# M4G7 register map
File version: 0.1
Registers are 32-bit, read-write, reset 0x0 unless marked. A register's access mark holds for its fields unless they carry their own. Offsets are from the block's base; [hi:lo] are bit positions; {n}, {i} and the like mark numbered series; 'fields as' and 'values as' point back to an identical list.

## SMI
Base 0x4000C000
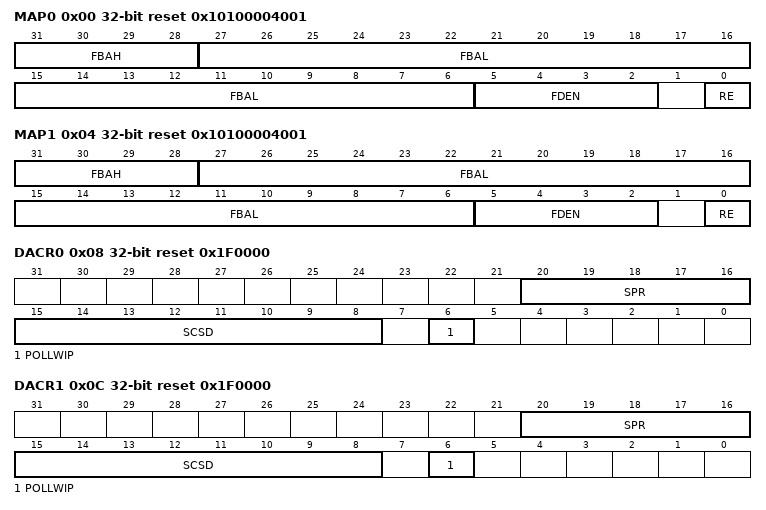
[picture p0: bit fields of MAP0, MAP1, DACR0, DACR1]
0x00 MAP0 reset 0x10100004001 — SMIF Flash Memory Map0 Register
  [31:28] FBAH ro, [27:6] FBAL, [5:2] FDEN, [0] RE
0x04 MAP1 reset 0x10100004001 — SMIF Flash Memory Map1 Register
  [31:28] FBAH ro, [27:6] FBAL, [5:2] FDEN, [0] RE
0x08 DACR0 reset 0x1F0000 — SMIF Direct Access Control Register 0
  [20:16] SPR, [15:8] SCSD, [6] POLLWIP
0x0C DACR1 reset 0x1F0000 — SMIF Direct Access Control Register 1
  [20:16] SPR, [15:8] SCSD, [6] POLLWIP
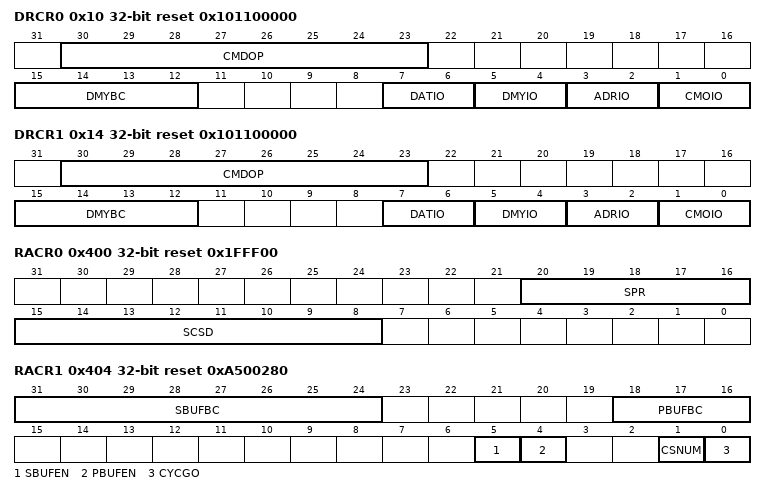
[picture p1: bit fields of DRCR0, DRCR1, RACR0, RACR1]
0x10 DRCR0 reset 0x101100000 — SMIF Direct Read Control Register 0
  [30:23] CMDOP, [15:12] DMYBC, [7:6] DATIO, [5:4] DMYIO, [3:2] ADRIO, [1:0] CMOIO
0x14 DRCR1 reset 0x101100000 — SMIF Direct Read Control Register 1
  fields as DRCR0
0x400 RACR0 reset 0x1FFF00 — SMIF Program Register Access Control Register 0
  [20:16] SPR, [15:8] SCSD
0x404 RACR1 reset 0xA500280 — SMIF Program Register Access Control Register 1
  [31:24] SBUFBC, [18:16] PBUFBC, [5] SBUFEN, [4] PBUFEN, [1] CSNUM, [0] CYCGO
0x408 INT — SMIF Program Register Access Interrupt Enable Register
  [0] INTEN
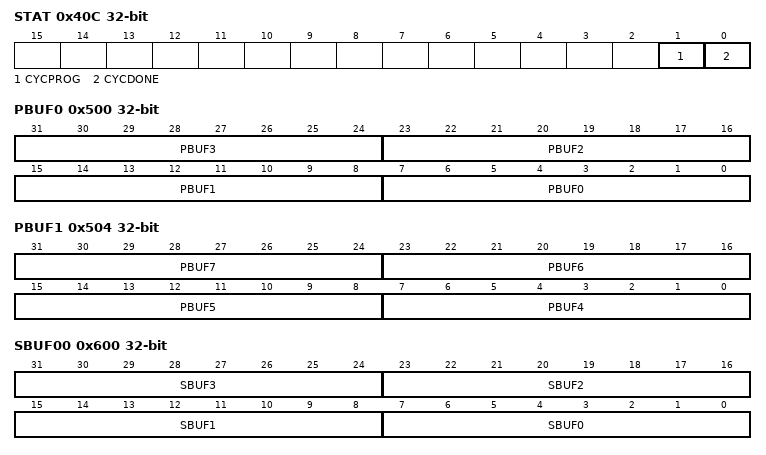
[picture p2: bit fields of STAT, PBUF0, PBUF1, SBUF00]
0x40C STAT — SMIF Program Register Access Status Register
  [1] CYCPROG ro, [0] CYCDONE
0x500 PBUF0 reset not defined — SMIF Program Register Primary Buffer Data Register 0
  [8n+7:8n] PBUF{n} (n=0..3)
0x504 PBUF1 reset not defined — SMIF Program Register Primary Buffer Data Register 1
  [8n-25:8n-32] PBUF{n} (n=4..7)
0x600 SBUF00 reset not defined — SMIF Program Register Secondary Buffer Data Register 00
  [8n+7:8n] SBUF{n} (n=0..3)
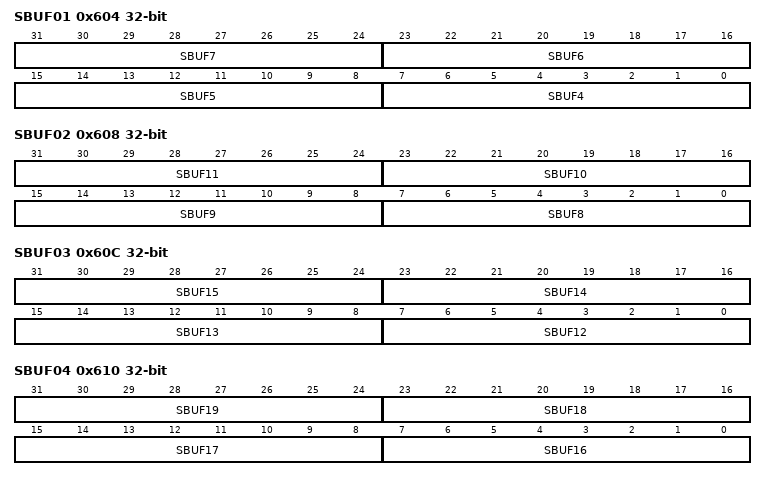
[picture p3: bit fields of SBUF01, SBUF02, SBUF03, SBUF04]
0x604 SBUF01 reset not defined — SMIF Program Register Secondary Buffer Data Register 01
  [8n-25:8n-32] SBUF{n} (n=4..7)
0x608 SBUF02 reset not defined — SMIF Program Register Secondary Buffer Data Register 02
  [8n-57:8n-64] SBUF{n} (n=8..11)
0x60C SBUF03 reset not defined — SMIF Program Register Secondary Buffer Data Register 03
  [8n-89:8n-96] SBUF{n} (n=12..15)
0x610 SBUF04 reset not defined — SMIF Program Register Secondary Buffer Data Register 04
  [8n-121:8n-128] SBUF{n} (n=16..19)
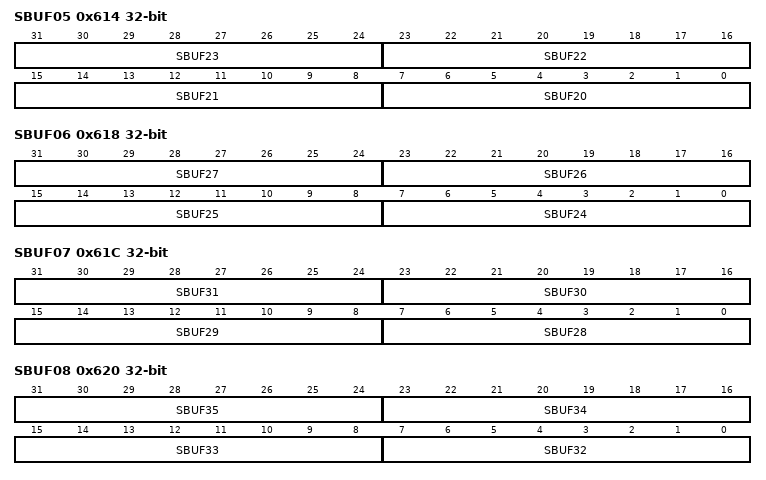
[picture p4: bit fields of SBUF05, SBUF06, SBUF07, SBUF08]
0x614 SBUF05 reset not defined — SMIF Program Register Secondary Buffer Data Register 05
  [8n-153:8n-160] SBUF{n} (n=20..23)
0x618 SBUF06 reset not defined — SMIF Program Register Secondary Buffer Data Register 06
  [8n-185:8n-192] SBUF{n} (n=24..27)
0x61C SBUF07 reset not defined — SMIF Program Register Secondary Buffer Data Register 07
  [8n-217:8n-224] SBUF{n} (n=28..31)
0x620 SBUF08 reset not defined — SMIF Program Register Secondary Buffer Data Register 08
  [8n-249:8n-256] SBUF{n} (n=32..35)
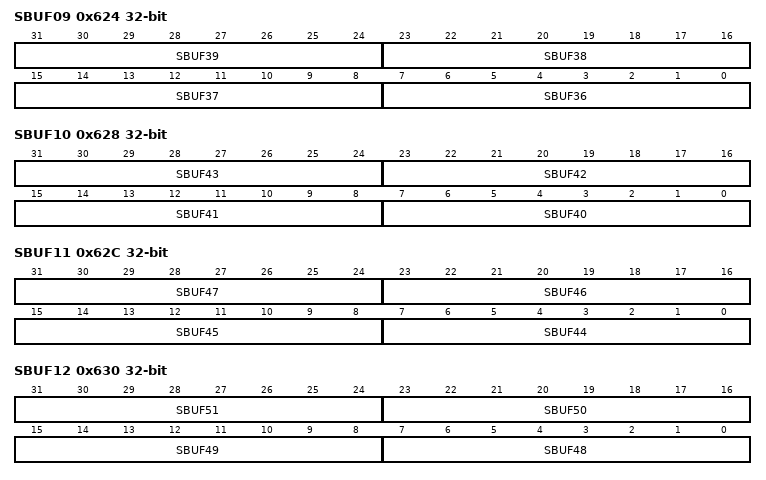
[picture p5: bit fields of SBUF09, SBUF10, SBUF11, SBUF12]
0x624 SBUF09 reset not defined — SMIF Program Register Secondary Buffer Data Register 09
  [8n-281:8n-288] SBUF{n} (n=36..39)
0x628 SBUF10 reset not defined — SMIF Program Register Secondary Buffer Data Register 10
  [8n-313:8n-320] SBUF{n} (n=40..43)
0x62C SBUF11 reset not defined — SMIF Program Register Secondary Buffer Data Register 11
  [8n-345:8n-352] SBUF{n} (n=44..47)
0x630 SBUF12 reset not defined — SMIF Program Register Secondary Buffer Data Register 12
  [8n-377:8n-384] SBUF{n} (n=48..51)
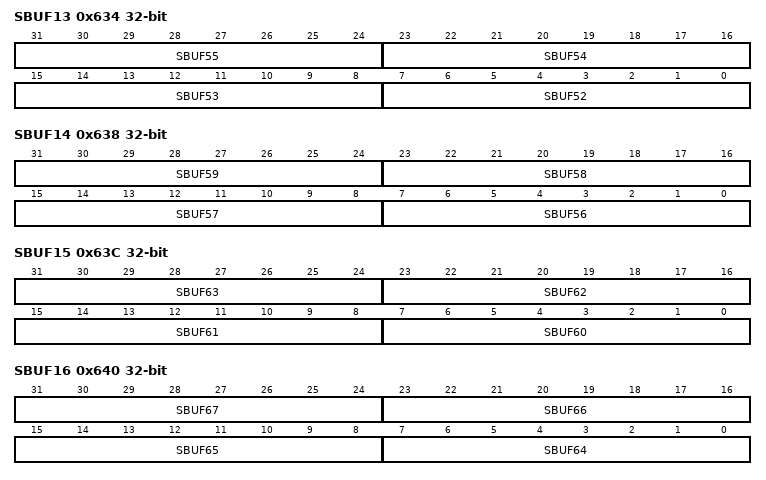
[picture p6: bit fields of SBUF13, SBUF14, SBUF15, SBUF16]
0x634 SBUF13 reset not defined — SMIF Program Register Secondary Buffer Data Register 13
  [8n-409:8n-416] SBUF{n} (n=52..55)
0x638 SBUF14 reset not defined — SMIF Program Register Secondary Buffer Data Register 14
  [8n-441:8n-448] SBUF{n} (n=56..59)
0x63C SBUF15 reset not defined — SMIF Program Register Secondary Buffer Data Register 15
  [8n-473:8n-480] SBUF{n} (n=60..63)
0x640 SBUF16 reset not defined — SMIF Program Register Secondary Buffer Data Register 16
  [8n-505:8n-512] SBUF{n} (n=64..67)
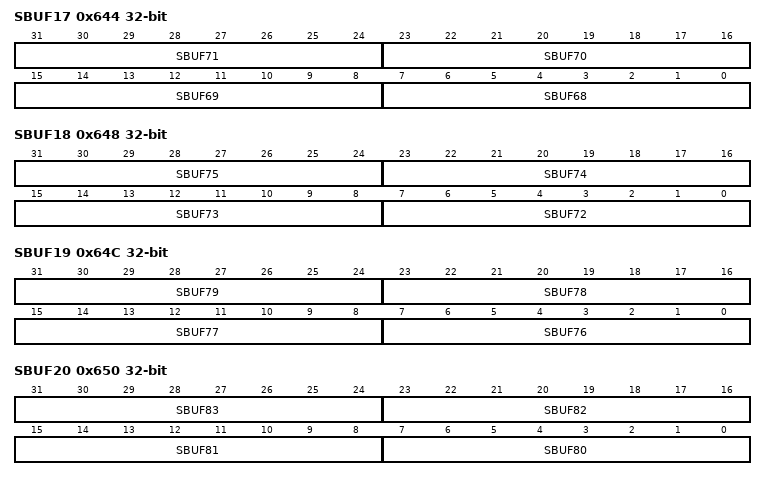
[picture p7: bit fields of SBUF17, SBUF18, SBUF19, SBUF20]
0x644 SBUF17 reset not defined — SMIF Program Register Secondary Buffer Data Register 17
  [8n-537:8n-544] SBUF{n} (n=68..71)
0x648 SBUF18 reset not defined — SMIF Program Register Secondary Buffer Data Register 18
  [8n-569:8n-576] SBUF{n} (n=72..75)
0x64C SBUF19 reset not defined — SMIF Program Register Secondary Buffer Data Register 19
  [8n-601:8n-608] SBUF{n} (n=76..79)
0x650 SBUF20 reset not defined — SMIF Program Register Secondary Buffer Data Register 20
  [8n-633:8n-640] SBUF{n} (n=80..83)
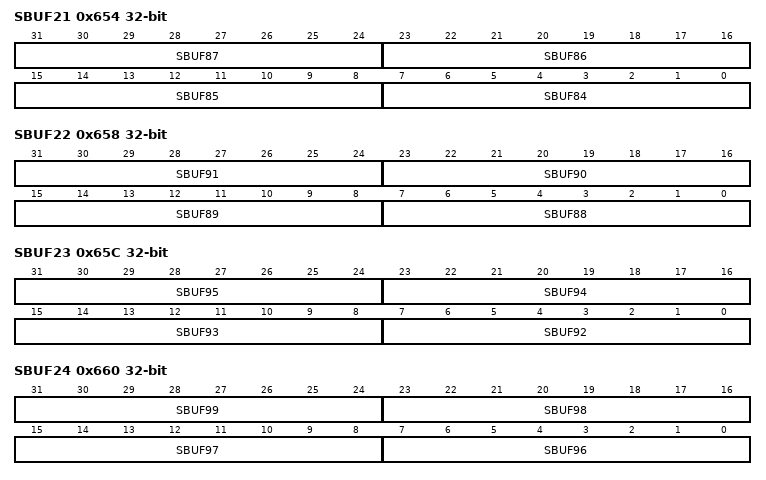
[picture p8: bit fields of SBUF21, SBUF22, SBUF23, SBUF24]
0x654 SBUF21 reset not defined — SMIF Program Register Secondary Buffer Data Register 21
  [8n-665:8n-672] SBUF{n} (n=84..87)
0x658 SBUF22 reset not defined — SMIF Program Register Secondary Buffer Data Register 22
  [8n-697:8n-704] SBUF{n} (n=88..91)
0x65C SBUF23 reset not defined — SMIF Program Register Secondary Buffer Data Register 23
  [8n-729:8n-736] SBUF{n} (n=92..95)
0x660 SBUF24 reset not defined — SMIF Program Register Secondary Buffer Data Register 24
  [8n-761:8n-768] SBUF{n} (n=96..99)
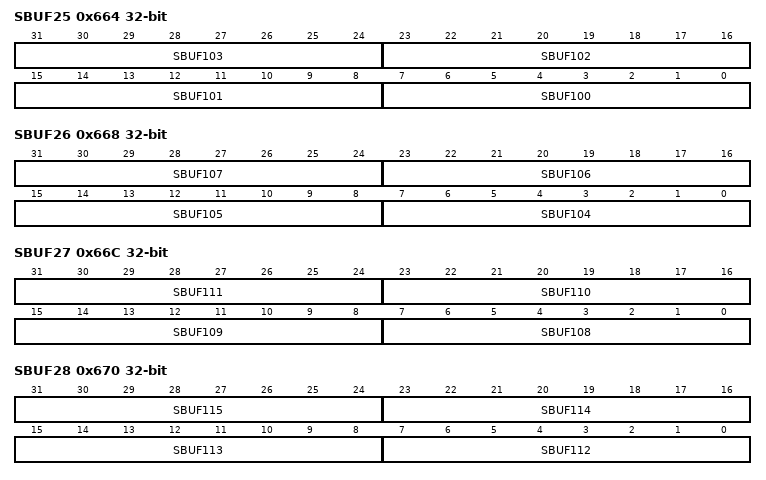
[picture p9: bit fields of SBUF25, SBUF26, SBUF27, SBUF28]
0x664 SBUF25 reset not defined — SMIF Program Register Secondary Buffer Data Register 25
  [8n-793:8n-800] SBUF{n} (n=100..103)
0x668 SBUF26 reset not defined — SMIF Program Register Secondary Buffer Data Register 26
  [8n-825:8n-832] SBUF{n} (n=104..107)
0x66C SBUF27 reset not defined — SMIF Program Register Secondary Buffer Data Register 27
  [8n-857:8n-864] SBUF{n} (n=108..111)
0x670 SBUF28 reset not defined — SMIF Program Register Secondary Buffer Data Register 28
  [8n-889:8n-896] SBUF{n} (n=112..115)
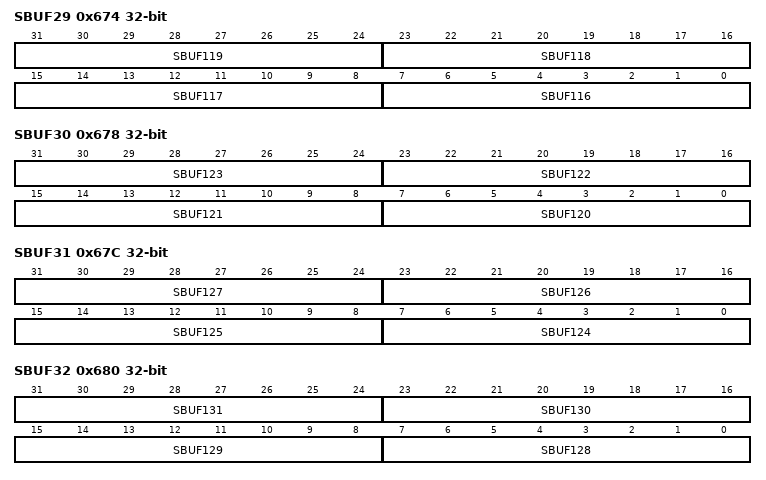
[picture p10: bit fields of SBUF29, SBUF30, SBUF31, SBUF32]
0x674 SBUF29 reset not defined — SMIF Program Register Secondary Buffer Data Register 29
  [8n-921:8n-928] SBUF{n} (n=116..119)
0x678 SBUF30 reset not defined — SMIF Program Register Secondary Buffer Data Register 30
  [8n-953:8n-960] SBUF{n} (n=120..123)
0x67C SBUF31 reset not defined — SMIF Program Register Secondary Buffer Data Register 31
  [8n-985:8n-992] SBUF{n} (n=124..127)
0x680 SBUF32 reset not defined — SMIF Program Register Secondary Buffer Data Register 32
  [8n-1017:8n-1024] SBUF{n} (n=128..131)
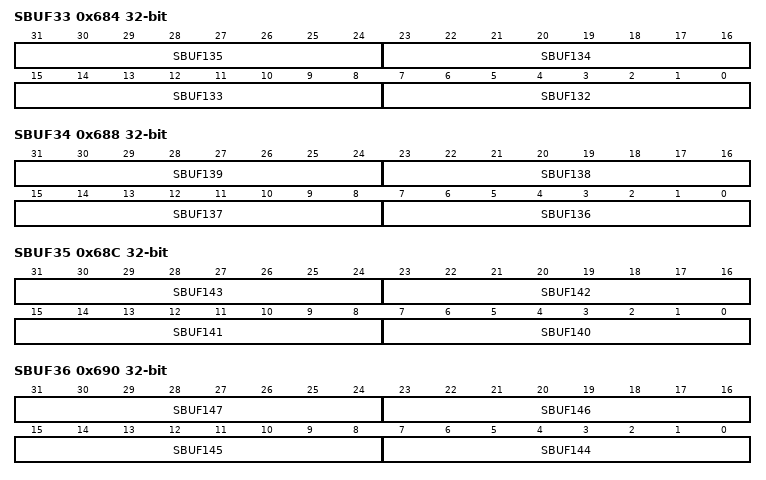
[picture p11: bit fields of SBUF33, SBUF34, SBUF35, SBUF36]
0x684 SBUF33 reset not defined — SMIF Program Register Secondary Buffer Data Register 33
  [8n-1049:8n-1056] SBUF{n} (n=132..135)
0x688 SBUF34 reset not defined — SMIF Program Register Secondary Buffer Data Register 34
  [8n-1081:8n-1088] SBUF{n} (n=136..139)
0x68C SBUF35 reset not defined — SMIF Program Register Secondary Buffer Data Register 35
  [8n-1113:8n-1120] SBUF{n} (n=140..143)
0x690 SBUF36 reset not defined — SMIF Program Register Secondary Buffer Data Register 36
  [8n-1145:8n-1152] SBUF{n} (n=144..147)
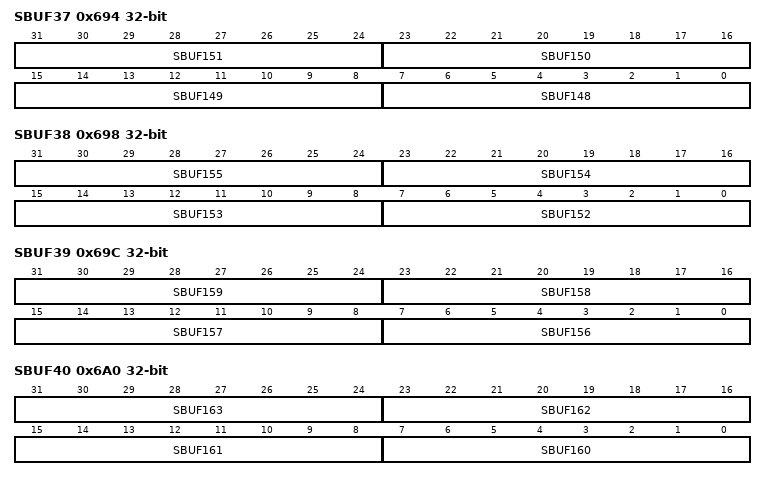
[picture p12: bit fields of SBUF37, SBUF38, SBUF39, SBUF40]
0x694 SBUF37 reset not defined — SMIF Program Register Secondary Buffer Data Register 37
  [8n-1177:8n-1184] SBUF{n} (n=148..151)
0x698 SBUF38 reset not defined — SMIF Program Register Secondary Buffer Data Register 38
  [8n-1209:8n-1216] SBUF{n} (n=152..155)
0x69C SBUF39 reset not defined — SMIF Program Register Secondary Buffer Data Register 39
  [8n-1241:8n-1248] SBUF{n} (n=156..159)
0x6A0 SBUF40 reset not defined — SMIF Program Register Secondary Buffer Data Register 40
  [8n-1273:8n-1280] SBUF{n} (n=160..163)
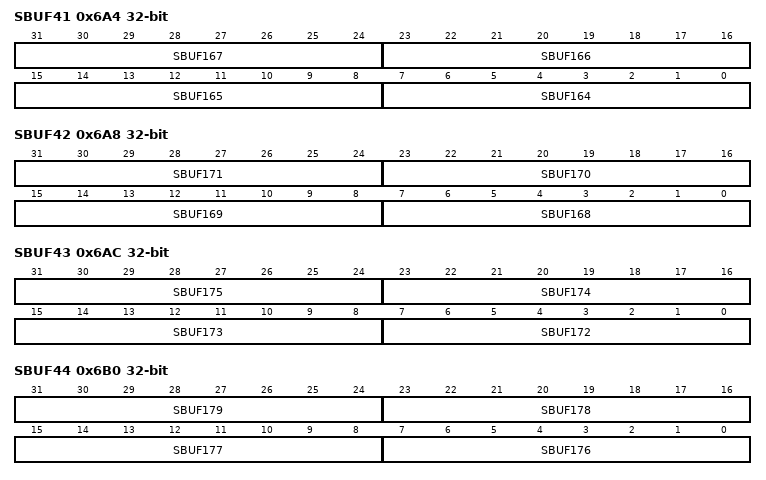
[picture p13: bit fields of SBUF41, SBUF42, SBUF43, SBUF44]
0x6A4 SBUF41 reset not defined — SMIF Program Register Secondary Buffer Data Register 41
  [8n-1305:8n-1312] SBUF{n} (n=164..167)
0x6A8 SBUF42 reset not defined — SMIF Program Register Secondary Buffer Data Register 42
  [8n-1337:8n-1344] SBUF{n} (n=168..171)
0x6AC SBUF43 reset not defined — SMIF Program Register Secondary Buffer Data Register 43
  [8n-1369:8n-1376] SBUF{n} (n=172..175)
0x6B0 SBUF44 reset not defined — SMIF Program Register Secondary Buffer Data Register 44
  [8n-1401:8n-1408] SBUF{n} (n=176..179)
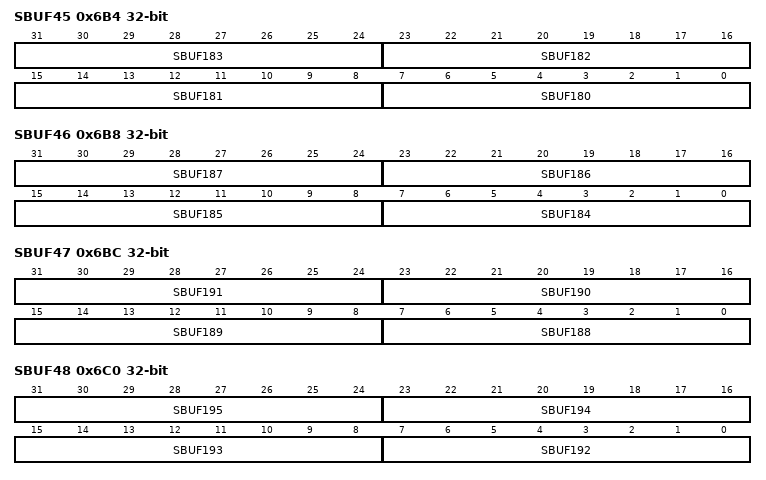
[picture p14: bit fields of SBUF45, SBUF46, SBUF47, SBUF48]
0x6B4 SBUF45 reset not defined — SMIF Program Register Secondary Buffer Data Register 45
  [8n-1433:8n-1440] SBUF{n} (n=180..183)
0x6B8 SBUF46 reset not defined — SMIF Program Register Secondary Buffer Data Register 46
  [8n-1465:8n-1472] SBUF{n} (n=184..187)
0x6BC SBUF47 reset not defined — SMIF Program Register Secondary Buffer Data Register 47
  [8n-1497:8n-1504] SBUF{n} (n=188..191)
0x6C0 SBUF48 reset not defined — SMIF Program Register Secondary Buffer Data Register 48
  [8n-1529:8n-1536] SBUF{n} (n=192..195)
0x6C4 SBUF49 reset not defined — SMIF Program Register Secondary Buffer Data Register 49
  [8n-1561:8n-1568] SBUF{n} (n=196..199)
0x6C8 SBUF50 reset not defined — SMIF Program Register Secondary Buffer Data Register 50
  [8n-1593:8n-1600] SBUF{n} (n=200..203)
0x6CC SBUF51 reset not defined — SMIF Program Register Secondary Buffer Data Register 51
  [8n-1625:8n-1632] SBUF{n} (n=204..207)
0x6D0 SBUF52 reset not defined — SMIF Program Register Secondary Buffer Data Register 52
  [8n-1657:8n-1664] SBUF{n} (n=208..211)
0x6D4 SBUF53 reset not defined — SMIF Program Register Secondary Buffer Data Register 53
  [8n-1689:8n-1696] SBUF{n} (n=212..215)
0x6D8 SBUF54 reset not defined — SMIF Program Register Secondary Buffer Data Register 54
  [8n-1721:8n-1728] SBUF{n} (n=216..219)
0x6DC SBUF55 reset not defined — SMIF Program Register Secondary Buffer Data Register 55
  [8n-1753:8n-1760] SBUF{n} (n=220..223)
0x6E0 SBUF56 reset not defined — SMIF Program Register Secondary Buffer Data Register 56
  [8n-1785:8n-1792] SBUF{n} (n=224..227)
0x6E4 SBUF57 reset not defined — SMIF Program Register Secondary Buffer Data Register 57
  [8n-1817:8n-1824] SBUF{n} (n=228..231)
0x6E8 SBUF58 reset not defined — SMIF Program Register Secondary Buffer Data Register 58
  [8n-1849:8n-1856] SBUF{n} (n=232..235)
0x6EC SBUF59 reset not defined — SMIF Program Register Secondary Buffer Data Register 59
  [8n-1881:8n-1888] SBUF{n} (n=236..239)
0x6F0 SBUF60 reset not defined — SMIF Program Register Secondary Buffer Data Register 60
  [8n-1913:8n-1920] SBUF{n} (n=240..243)
0x6F4 SBUF61 reset not defined — SMIF Program Register Secondary Buffer Data Register 61
  [8n-1945:8n-1952] SBUF{n} (n=244..247)
0x6F8 SBUF62 reset not defined — SMIF Program Register Secondary Buffer Data Register 62
  [8n-1977:8n-1984] SBUF{n} (n=248..251)
0x6FC SBUF63 reset not defined — SMIF Program Register Secondary Buffer Data Register 63
  [8n-2009:8n-2016] SBUF{n} (n=252..255)
